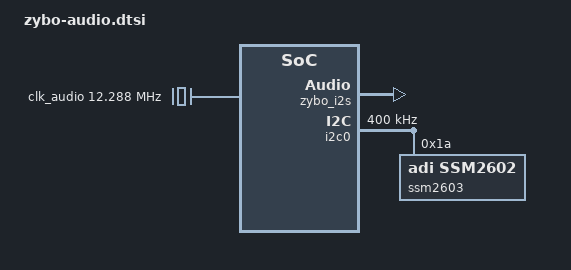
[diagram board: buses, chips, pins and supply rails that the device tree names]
/*
 * zybo-audio.dtsi — ZYBO Audio DSP Device Tree Overlay
 *
 * CPU DAI: zybo-i2s-dai (custom driver for d_axi_i2s_audio IP)
 * Codec:   ssm2602-hifi (mainline SSM2602 driver, SSM2603 compatible)
 */

/ {
	clk_audio: audio_clock {
		compatible = "fixed-clock";
		#clock-cells = <0>;
		clock-frequency = <12288000>;
	};

	sound {
		compatible = "simple-audio-card";
		simple-audio-card,name = "ZYBO Audio DSP";
		simple-audio-card,format = "i2s";
		simple-audio-card,cpu { sound-dai = <&zybo_i2s>; };
		simple-audio-card,codec { sound-dai = <&ssm2603>; };
	};
};

&amba_pl {
	axi_dma_audio: dma@40400000 {
		compatible = "xlnx,axi-dma-1.00.a";
		reg = <0x40400000 0x10000>;
		#dma-cells = <1>;
		clocks = <&clkc 15>;
		interrupt-parent = <&intc>;
		interrupts = <0 29 4>, <0 30 4>;
		dma-channel@0 { compatible = "xlnx,axi-dma-mm2s-channel"; interrupts = <0 29 4>; };
		dma-channel@1 { compatible = "xlnx,axi-dma-s2mm-channel"; interrupts = <0 30 4>; };
	};

	zybo_i2s: i2s@43c00000 {
		compatible = "digilent,d_axi_i2s_audio-2.0";
		reg = <0x43c00000 0x10000>;
		clocks = <&clkc 15>;
		dmas = <&axi_dma_audio 0>, <&axi_dma_audio 1>;
		dma-names = "tx", "rx";
	};
};

&i2c0 {
	status = "okay";
	clock-frequency = <400000>;
	ssm2603: codec@1a {
		compatible = "adi,ssm2602";
		reg = <0x1a>;
		#sound-dai-cells = <0>;
	};
};
